AUTOSAR XML (schema 4-0-3)
package /ComponentType
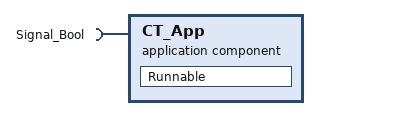
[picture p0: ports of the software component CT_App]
  application sw component type CT_App
    require port Signal_Bool: nonqueued-receiver-com-spec{data-element=Signal_Bool, filter=data-filter-type=ALWAYS, init-value=constant-reference=cInit}, required-interface=Signal_Bool
    behavior CT_App_InternalBehavior: port-api-option{enable-take-address=false, indirect-api=false, port=CT_App/Signal_Bool}
      data received event DRT_Runnable_Signal_Bool_Signal_Bool: start-on-event=Runnable, data=Signal_Bool.Signal_Bool
      runnable Runnable
  swc implementation CT_App_Implementation: behavior=CT_App_InternalBehavior
    code-descriptors:
      code Code: artifact-descriptors=autosar-engineering-object=category=SWSRC
package /Constant
  constant specification cInit: value-spec=1
package /DataType
  impl type Signal_Bool: category=VALUE, base-type=Signal_Bool, range raw 0..1
package /DaVinci/ABC_ClusterCANCluster
  can cluster CANCluster: speed=0
    can physical channel New_CAN_Network_1: comm-connectors=CANCluster_e_Rx_simple
      frame Msg_Bool: id 0x0, to e_Rx_simple, frame-length=8, can-addressing-mode=STANDARD
        pdu Msg_Bool: length=64
          signal Signal_Bool_Msg_Bool: start 0, 1 bit, little-endian, to e_Rx_simple
package /DaVinci/ABC_ECU
  ecu instance e_Rx_simple: associated-pdur-i-pdu-group=[e_Rx_simple_CANCluster_Rx, e_Rx_simple_CANCluster_Tx], diagnostic-address=0, sleep-mode-supported=false, wake-up-over-bus-supported=false
    can communication controller CANCluster
    can communication connector CANCluster_e_Rx_simple: comm-controller=CANCluster
package /DaVinci/ABC_PDUGroup
  pdur i pdu group e_Rx_simple_CANCluster_Rx
  pdur i pdu group e_Rx_simple_CANCluster_Tx
package /ECUComposition
  composition sw component type EcuSwComposition
package /ECUCompositionType
  composition sw component type EcuSwComposition
    require port Signal_Bool: nonqueued-receiver-com-spec{data-element=Signal_Bool, filter=data-filter-type=ALWAYS}, required-interface=Signal_Bool
    component CP_App: type=CT_App
    delegate CP_App.Signal_Bool <-> outer port EcuSwComposition/Signal_Bool
package /PortInterface
  sender receiver interface Signal_Bool
    data Signal_Bool: type=Signal_Bool
package /VehicleProject
  system e_Rx_simple
    system mapping e_Rx_simple_MPPNG: sender-receiver-to-signal-mapping{data-element=CP_App.EcuSwComposition.Signal_Bool.Signal_Bool, system-signal=Signal_Bool}
    root-software-compositions:
      root sw composition prototype EcuSwComposition: software-composition=ECUCompositionType/EcuSwComposition
package /AR4_TemporaryElements/BaseType
  base type Signal_Bool: base-type-encoding=NONE, native-declaration=uint8
